AUTOSAR XML (schema 4-2-1)
package /VehicleProject
  system System
package /TP
  can tp config CAN00_CAN: communication-cluster=CAN00, can-tp-ecu{cycle-time-main-function=0.005, ecu-instance=MyECU}
    can tp channel TPCH: channel-id=0, channel-mode=FULL-DUPLEX-MODE
    tp-connections:
      addressing-format=STANDARD, can-tp-channel=TPCH, data-pdu=msg_diag_RequestGlobal_Tp_oCAN00, receiver=TN_MyECU, ta-type=FUNCTIONAL, tp-sdu=msg_diag_RequestGlobal_oCAN00, transmitter=TN_Tester
      addressing-format=STANDARD, can-tp-channel=TPCH, data-pdu=msg_diag_Response_MyECU_Tp_oCAN00, flow-control-pdu=msg_diag_Request_MyECU_Tp_oCAN00, receiver=TN_Tester, ta-type=PHYSICAL, tp-sdu=msg_diag_Response_MyECU_oCAN00, transmitter=TN_MyECU
      addressing-format=STANDARD, can-tp-channel=TPCH, data-pdu=msg_diag_Request_MyECU_Tp_oCAN00, flow-control-pdu=msg_diag_Response_MyECU_Tp_oCAN00, receiver=TN_MyECU, ta-type=PHYSICAL, tp-sdu=msg_diag_Request_MyECU_oCAN00, transmitter=TN_Tester
    can tp node TN_MyECU: connector=CN_CAN00
    can tp node TN_Tester
package /Cluster
  can cluster CAN00: protocol-name=CAN
    can physical channel CHNL: comm-connectors=CN_CAN00
      frame msg_diag_Request_MyECU_oCAN00: id 0x610, to MyECU, frame-length=8, can-addressing-mode=STANDARD
        n pdu msg_diag_Request_MyECU_Tp_oCAN00: length=8
      frame msg_diag_RequestGlobal_oCAN00: id 0x614, to MyECU, frame-length=8, can-addressing-mode=STANDARD
        n pdu msg_diag_RequestGlobal_Tp_oCAN00: length=8
      frame msg_diag_Response_MyECU_oCAN00: id 0x612, from MyECU, frame-length=8, can-addressing-mode=STANDARD
        n pdu msg_diag_Response_MyECU_Tp_oCAN00: length=8
      frame msg_MyECU_2_Rear_oCAN00: id 0x200, from MyECU, frame-length=6, can-addressing-mode=STANDARD
        pdu msg_MyECU_2_Rear_oCAN00: length=6, minimum-delay=0, transmission-mode-false-timing=cyclic-timing={time-offset=0, time-period=0.1}, transmission-mode-true-timing=cyclic-timing={time-offset=0, time-period=0.1}, unused-bit-pattern=0
          signal sig_SpeedLimit_omsg_MyECU_2_Rear_oCAN00: start 0, 8 bit, little-endian, init-value=0, base-type=uint8, compu-method=CM_sig_SpeedLimit, transfer-property=PENDING
          signal sig_BatteryStatus_omsg_MyECU_2_Rear_oCAN00: start 16, 8 bit, little-endian, init-value=0, base-type=uint8, compu-method=CM_sig_BatteryStatus, transfer-property=PENDING
      frame msg_nm_MyECU_oCAN00: id 0x400, from MyECU, frame-length=8, can-addressing-mode=STANDARD
        nm pdu msg_nm_MyECU_oCAN00: length=8, unused-bit-pattern=0
      frame msg_nm_RearECU_oCAN00: id 0x401, to MyECU, frame-length=8, can-addressing-mode=STANDARD
        nm pdu msg_nm_RearECU_oCAN00: length=8, unused-bit-pattern=0
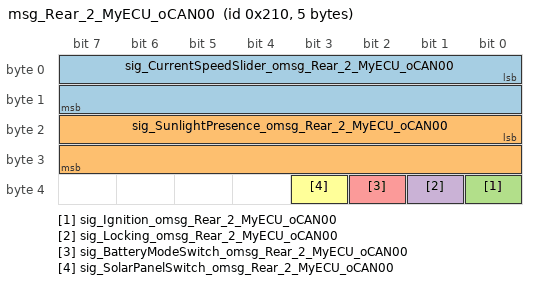
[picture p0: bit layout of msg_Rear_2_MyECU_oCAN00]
      frame msg_Rear_2_MyECU_oCAN00: id 0x210, to MyECU, frame-length=5, can-addressing-mode=STANDARD
        pdu msg_Rear_2_MyECU_oCAN00: length=5, minimum-delay=0, transmission-mode-false-timing=cyclic-timing={time-offset=0, time-period=0.1}, transmission-mode-true-timing=cyclic-timing={time-offset=0, time-period=0.1}, unused-bit-pattern=0
          signal sig_CurrentSpeedSlider_omsg_Rear_2_MyECU_oCAN00: start 0, 16 bit, little-endian, init-value=0, base-type=uint16, compu-method=CM_sig_CurrentSpeedSlider, transfer-property=PENDING, to MyECU
          signal sig_SunlightPresence_omsg_Rear_2_MyECU_oCAN00: start 16, 16 bit, little-endian, init-value=0, base-type=uint16, compu-method=CM_sig_SunlightPresence, transfer-property=PENDING, to MyECU
          signal sig_Ignition_omsg_Rear_2_MyECU_oCAN00: start 32, 1 bit, little-endian, init-value=0, base-type=boolean, compu-method=CM_sig_Ignition, transfer-property=PENDING, to MyECU
          signal sig_Locking_omsg_Rear_2_MyECU_oCAN00: start 33, 1 bit, little-endian, init-value=0, base-type=boolean, compu-method=CM_sig_Locking, transfer-property=PENDING, to MyECU
          signal sig_BatteryModeSwitch_omsg_Rear_2_MyECU_oCAN00: start 34, 1 bit, little-endian, init-value=0, base-type=boolean, compu-method=CM_sig_BatteryModeSwitch, transfer-property=PENDING, to MyECU
          signal sig_SolarPanelSwitch_omsg_Rear_2_MyECU_oCAN00: start 35, 1 bit, little-endian, init-value=0, base-type=boolean, compu-method=CM_sig_SolarPanelSwitch, transfer-property=PENDING, to MyECU
      pdu triggering PT_msg_diag_Request_MyECU: pdu=msg_diag_Request_MyECU_oCAN00, to MyECU
      pdu triggering PT_msg_diag_RequestGlobal: pdu=msg_diag_RequestGlobal_oCAN00, to MyECU
      pdu triggering PT_msg_diag_Response_MyECU: pdu=msg_diag_Response_MyECU_oCAN00, from MyECU
package /ECU
  ecu instance MyECU: associated-com-i-pdu-group=[MyECU_oCAN00_Rx, MyECU_oCAN00_Tx]
    can communication controller CT_CAN00
    can communication connector CN_CAN00: comm-controller=CT_CAN00
package /IPDUGroup
  i signal i pdu group MyECU_oCAN00_Rx: communication-direction=IN, i-signal-i-pdus=msg_Rear_2_MyECU_oCAN00
  i signal i pdu group MyECU_oCAN00_Tx: communication-direction=OUT, i-signal-i-pdus=msg_MyECU_2_Rear_oCAN00
package /PDU
  dcm i pdu msg_diag_Request_MyECU_oCAN00: length=8, diag-pdu-type=DIAG-REQUEST
  dcm i pdu msg_diag_RequestGlobal_oCAN00: length=7, diag-pdu-type=DIAG-REQUEST
  dcm i pdu msg_diag_Response_MyECU_oCAN00: length=8, diag-pdu-type=DIAG-RESPONSE
